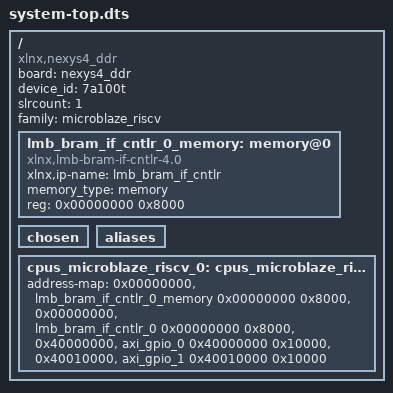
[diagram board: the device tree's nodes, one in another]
/dts-v1/;
#include "pl.dtsi"
/ {
	board = "nexys4_ddr";
	compatible = "xlnx,nexys4_ddr";
	device_id = "7a100t";
	#address-cells = <1>;
	#size-cells = <1>;
	slrcount = <1>;
	family = "microblaze_riscv";
	lmb_bram_if_cntlr_0_memory: memory@0 {
		compatible = "xlnx,lmb-bram-if-cntlr-4.0";
		xlnx,ip-name = "lmb_bram_if_cntlr";
		device_type = "memory";
		memory_type = "memory";
		reg = <0x00000000 0x8000>;
	};
	chosen {
	};
	aliases {
	};
	cpus_microblaze_riscv_0: cpus_microblaze_riscv@0 {
		address-map = <0x00000000 &lmb_bram_if_cntlr_0_memory 0x00000000 0x8000>, 
			      <0x00000000 &lmb_bram_if_cntlr_0 0x00000000 0x8000>, 
			      <0x40000000 &axi_gpio_0 0x40000000 0x10000>, 
			      <0x40010000 &axi_gpio_1 0x40010000 0x10000>;
		#ranges-address-cells = <0x1>;
		#ranges-size-cells = <0x1>;
	};
};
